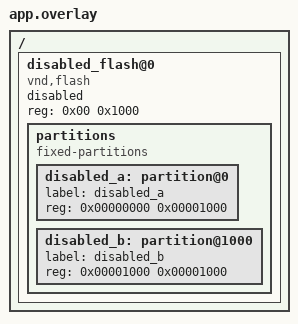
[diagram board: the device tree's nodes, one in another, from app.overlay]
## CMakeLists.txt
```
# SPDX-License-Identifier: Apache-2.0

cmake_minimum_required(VERSION 3.20.0)
find_package(Zephyr REQUIRED HINTS $ENV{ZEPHYR_BASE})
project(flash_map)

FILE(GLOB app_sources src/*.c)
target_sources(app PRIVATE ${app_sources})
```

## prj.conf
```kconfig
CONFIG_ZTEST=y
CONFIG_ZTEST_STACK_SIZE=2048
CONFIG_FLASH=y
CONFIG_FLASH_PAGE_LAYOUT=y
CONFIG_FLASH_MAP=y
CONFIG_FLASH_AREA_CHECK_INTEGRITY=y
```

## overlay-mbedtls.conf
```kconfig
CONFIG_FLASH_AREA_CHECK_INTEGRITY_MBEDTLS=y
```

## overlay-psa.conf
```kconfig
CONFIG_FLASH_AREA_CHECK_INTEGRITY_PSA=y
CONFIG_MBEDTLS=y
CONFIG_MBEDTLS_PSA_CRYPTO_C=y
```

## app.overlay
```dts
/*
 * Copyright (c) 2022, Commonwealth Scientific and Industrial Research
 * Organisation (CSIRO) ABN 41 687 119 230.
 *
 * SPDX-License-Identifier: Apache-2.0
 *
 * Test compilation with disabled flash nodes.
 */

/{
	disabled_flash@0 {
		compatible = "vnd,flash";
		reg = <0x00 0x1000>;
		status = "disabled";

		partitions {
			compatible = "fixed-partitions";
			#address-cells = <1>;
			#size-cells = <1>;

			disabled_a: partition@0 {
				label = "disabled_a";
				reg = <0x00000000 0x00001000>;
			};
			disabled_b: partition@1000 {
				label = "disabled_b";
				reg = <0x00001000 0x00001000>;
			};
		};
	};
};
```

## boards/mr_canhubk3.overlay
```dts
/*
 * Copyright 2023 NXP
 *
 * SPDX-License-Identifier: Apache-2.0
 */

#include "../app.overlay"

/*
 * Currently there's no support for mcuboot, so create a partition for this test.
 */
&mx25l6433f {
	partitions {
		slot1_partition: partition@100000 {
			reg = <0x100000 0x100000>;
		};
	};
};
```

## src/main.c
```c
/*
 * Copyright (c) 2017 Nordic Semiconductor ASA
 * Copyright (c) 2015 Runtime Inc
 * Copyright (c) 2020 Gerson Fernando Budke <nandojve@gmail.com>
 * Copyright 2024 NXP
 *
 * SPDX-License-Identifier: Apache-2.0
 */

#include <zephyr/ztest.h>
#include <zephyr/drivers/flash.h>
#include <zephyr/storage/flash_map.h>

#define SLOT1_PARTITION		slot1_partition
#define SLOT1_PARTITION_ID	FIXED_PARTITION_ID(SLOT1_PARTITION)
#define SLOT1_PARTITION_DEV	FIXED_PARTITION_DEVICE(SLOT1_PARTITION)
#define SLOT1_PARTITION_NODE	DT_NODELABEL(SLOT1_PARTITION)

extern int flash_map_entries;
struct flash_sector fs_sectors[1024];

ZTEST(flash_map, test_flash_area_disabled_device)
{
	const struct flash_area *fa;
	int rc;

	/* Test that attempting to open a disabled flash area fails */
	rc = flash_area_open(FIXED_PARTITION_ID(disabled_a), &fa);
	zassert_equal(rc, -ENODEV, "Open did not fail");
	rc = flash_area_open(FIXED_PARTITION_ID(disabled_b), &fa);
	zassert_equal(rc, -ENODEV, "Open did not fail");
}

/**
 * @brief Test flash_area_get_sectors()
 */
ZTEST(flash_map, test_flash_area_get_sectors)
{
	const struct flash_area *fa;
	uint32_t sec_cnt;
	int i;
	int rc;
	off_t off;
	uint8_t wd[512];
	uint8_t rd[512];
	const struct device *flash_dev;
	const struct device *flash_dev_a = SLOT1_PARTITION_DEV;

	rc = flash_area_open(SLOT1_PARTITION_ID, &fa);
	zassert_true(rc == 0, "flash_area_open() fail");

	/* First erase the area so it's ready for use. */
	flash_dev = flash_area_get_device(fa);

	/* Device obtained by label should match the one from fa object */
	zassert_equal(flash_dev, flash_dev_a, "Device for slot1_partition do not match");

	rc = flash_erase(flash_dev, fa->fa_off, fa->fa_size);
	zassert_true(rc == 0, "flash area erase fail");

	(void)memset(wd, 0xa5, sizeof(wd));

	sec_cnt = ARRAY_SIZE(fs_sectors);
	rc = flash_area_get_sectors(SLOT1_PARTITION_ID, &sec_cnt, fs_sectors);
	zassert_true(rc == 0, "flash_area_get_sectors failed");

	/* write stuff to beginning of every sector */
	off = 0;
	for (i = 0; i < sec_cnt; i++) {
		rc = flash_area_write(fa, off, wd, sizeof(wd));
		zassert_true(rc == 0, "flash_area_write() fail");

		/* read it back via hal_flash_Read() */
		rc = flash_read(flash_dev, fa->fa_off + off, rd, sizeof(rd));
		zassert_true(rc == 0, "hal_flash_read() fail");

		rc = memcmp(wd, rd, sizeof(wd));
		zassert_true(rc == 0, "read data != write data");

		/* write stuff to end of area */
		rc = flash_write(flash_dev, fa->fa_off + off +
					    fs_sectors[i].fs_size - sizeof(wd),
				 wd, sizeof(wd));
		zassert_true(rc == 0, "hal_flash_write() fail");

		/* and read it back */
		(void)memset(rd, 0, sizeof(rd));
		rc = flash_area_read(fa, off + fs_sectors[i].fs_size -
					 sizeof(rd),
				     rd, sizeof(rd));
		zassert_true(rc == 0, "hal_flash_read() fail");

		rc = memcmp(wd, rd, sizeof(rd));
		zassert_true(rc == 0, "read data != write data");

		off += fs_sectors[i].fs_size;
	}

	/* erase it */
	rc = flash_area_erase(fa, 0, fa->fa_size);
	zassert_true(rc == 0, "read data != write data");

	/* should read back ff all throughout*/
	(void)memset(wd, 0xff, sizeof(wd));
	for (off = 0; off < fa->fa_size; off += sizeof(rd)) {
		rc = flash_area_read(fa, off, rd, sizeof(rd));
		zassert_true(rc == 0, "hal_flash_read() fail");

		rc = memcmp(wd, rd, sizeof(rd));
		zassert_true(rc == 0, "area not erased");
	}

	flash_area_close(fa);
}

ZTEST(flash_map, test_flash_area_check_int_sha256)
{
	/* for i in {1..16}; do echo $'0123456789abcdef\nfedcba98765432' >> tst.sha; done
	 * hexdump tst.sha
	 */
	uint8_t tst_vec[] = { 0x30, 0x31, 0x32, 0x33, 0x34, 0x35, 0x36, 0x37,
			      0x38, 0x39, 0x61, 0x62, 0x63, 0x64, 0x65, 0x66,
			      0x0a, 0x66, 0x65, 0x64, 0x63, 0x62, 0x61, 0x39,
			      0x38, 0x37, 0x36, 0x35, 0x34, 0x33, 0x32, 0x0a,
			      0x30, 0x31, 0x32, 0x33, 0x34, 0x35, 0x36, 0x37,
			      0x38, 0x39, 0x61, 0x62, 0x63, 0x64, 0x65, 0x66,
			      0x0a, 0x66, 0x65, 0x64, 0x63, 0x62, 0x61, 0x39,
			      0x38, 0x37, 0x36, 0x35, 0x34, 0x33, 0x32, 0x0a,
			      0x30, 0x31, 0x32, 0x33, 0x34, 0x35, 0x36, 0x37,
			      0x38, 0x39, 0x61, 0x62, 0x63, 0x64, 0x65, 0x66,
			      0x0a, 0x66, 0x65, 0x64, 0x63, 0x62, 0x61, 0x39,
			      0x38, 0x37, 0x36, 0x35, 0x34, 0x33, 0x32, 0x0a,
			      0x30, 0x31, 0x32, 0x33, 0x34, 0x35, 0x36, 0x37,
			      0x38, 0x39, 0x61, 0x62, 0x63, 0x64, 0x65, 0x66,
			      0x0a, 0x66, 0x65, 0x64, 0x63, 0x62, 0x61, 0x39,
			      0x38, 0x37, 0x36, 0x35, 0x34, 0x33, 0x32, 0x0a,
			      0x30, 0x31, 0x32, 0x33, 0x34, 0x35, 0x36, 0x37,
			      0x38, 0x39, 0x61, 0x62, 0x63, 0x64, 0x65, 0x66,
			      0x0a, 0x66, 0x65, 0x64, 0x63, 0x62, 0x61, 0x39,
			      0x38, 0x37, 0x36, 0x35, 0x34, 0x33, 0x32, 0x0a,
			      0x30, 0x31, 0x32, 0x33, 0x34, 0x35, 0x36, 0x37,
			      0x38, 0x39, 0x61, 0x62, 0x63, 0x64, 0x65, 0x66,
			      0x0a, 0x66, 0x65, 0x64, 0x63, 0x62, 0x61, 0x39,
			      0x38, 0x37, 0x36, 0x35, 0x34, 0x33, 0x32, 0x0a,
			      0x30, 0x31, 0x32, 0x33, 0x34, 0x35, 0x36, 0x37,
			      0x38, 0x39, 0x61, 0x62, 0x63, 0x64, 0x65, 0x66,
			      0x0a, 0x66, 0x65, 0x64, 0x63, 0x62, 0x61, 0x39,
			      0x38, 0x37, 0x36, 0x35, 0x34, 0x33, 0x32, 0x0a,
			      0x30, 0x31, 0x32, 0x33, 0x34, 0x35, 0x36, 0x37,
			      0x38, 0x39, 0x61, 0x62, 0x63, 0x64, 0x65, 0x66,
			      0x0a, 0x66, 0x65, 0x64, 0x63, 0x62, 0x61, 0x39,
			      0x38, 0x37, 0x36, 0x35, 0x34, 0x33, 0x32, 0x0a,
			      0x30, 0x31, 0x32, 0x33, 0x34, 0x35, 0x36, 0x37,
			      0x38, 0x39, 0x61, 0x62, 0x63, 0x64, 0x65, 0x66,
			      0x0a, 0x66, 0x65, 0x64, 0x63, 0x62, 0x61, 0x39,
			      0x38, 0x37, 0x36, 0x35, 0x34, 0x33, 0x32, 0x0a,
			      0x30, 0x31, 0x32, 0x33, 0x34, 0x35, 0x36, 0x37,
			      0x38, 0x39, 0x61, 0x62, 0x63, 0x64, 0x65, 0x66,
			      0x0a, 0x66, 0x65, 0x64, 0x63, 0x62, 0x61, 0x39,
			      0x38, 0x37, 0x36, 0x35, 0x34, 0x33, 0x32, 0x0a,
			      0x30, 0x31, 0x32, 0x33, 0x34, 0x35, 0x36, 0x37,
			      0x38, 0x39, 0x61, 0x62, 0x63, 0x64, 0x65, 0x66,
			      0x0a, 0x66, 0x65, 0x64, 0x63, 0x62, 0x61, 0x39,
			      0x38, 0x37, 0x36, 0x35, 0x34, 0x33, 0x32, 0x0a,
			      0x30, 0x31, 0x32, 0x33, 0x34, 0x35, 0x36, 0x37,
			      0x38, 0x39, 0x61, 0x62, 0x63, 0x64, 0x65, 0x66,
			      0x0a, 0x66, 0x65, 0x64, 0x63, 0x62, 0x61, 0x39,
			      0x38, 0x37, 0x36, 0x35, 0x34, 0x33, 0x32, 0x0a,
			      0x30, 0x31, 0x32, 0x33, 0x34, 0x35, 0x36, 0x37,
			      0x38, 0x39, 0x61, 0x62, 0x63, 0x64, 0x65, 0x66,
			      0x0a, 0x66, 0x65, 0x64, 0x63, 0x62, 0x61, 0x39,
			      0x38, 0x37, 0x36, 0x35, 0x34, 0x33, 0x32, 0x0a,
			      0x30, 0x31, 0x32, 0x33, 0x34, 0x35, 0x36, 0x37,
			      0x38, 0x39, 0x61, 0x62, 0x63, 0x64, 0x65, 0x66,
			      0x0a, 0x66, 0x65, 0x64, 0x63, 0x62, 0x61, 0x39,
			      0x38, 0x37, 0x36, 0x35, 0x34, 0x33, 0x32, 0x0a,
			      0x30, 0x31, 0x32, 0x33, 0x34, 0x35, 0x36, 0x37,
			      0x38, 0x39, 0x61, 0x62, 0x63, 0x64, 0x65, 0x66,
			      0x0a, 0x66, 0x65, 0x64, 0x63, 0x62, 0x61, 0x39,
			      0x38, 0x37, 0x36, 0x35, 0x34, 0x33, 0x32, 0x0a,
			      0x30, 0x31, 0x32, 0x33, 0x34, 0x35, 0x36, 0x37,
			      0x38, 0x39, 0x61, 0x62, 0x63, 0x64, 0x65, 0x66,
			      0x0a, 0x66, 0x65, 0x64, 0x63, 0x62, 0x61, 0x39,
			      0x38, 0x37, 0x36, 0x35, 0x34, 0x33, 0x32, 0x0a };
	/* sha256sum tst.sha */
	uint8_t tst_sha[] = { 0xae, 0xed, 0x7d, 0x59, 0x53, 0xbd, 0xb7, 0x28,
			      0x3e, 0x59, 0xc2, 0x65, 0x59, 0x62, 0xe3, 0x7e,
			      0xfa, 0x97, 0xbd, 0x76, 0xf6, 0xac, 0xc3, 0x92,
			      0x59, 0x48, 0x4e, 0xc0, 0xaf, 0xa8, 0x49, 0x65 };

	const struct flash_area *fa;
	struct flash_area_check fac = { NULL, 0, -1, NULL, 0 };
	uint8_t buffer[16];
	int rc;

	rc = flash_area_open(SLOT1_PARTITION_ID, &fa);
	zassert_true(rc == 0, "flash_area_open() fail, error %d\n", rc);
	rc = flash_area_erase(fa, 0, fa->fa_size);
	zassert_true(rc == 0, "Flash erase failure (%d), error %d\n", rc);
	rc = flash_area_write(fa, 0, tst_vec, sizeof(tst_vec));
	zassert_true(rc == 0, "Flash img write, error %d\n", rc);

	rc = flash_area_check_int_sha256(NULL, NULL);
	zassert_true(rc == -EINVAL, "Flash area check int 256 params 1, 2\n");
	rc = flash_area_check_int_sha256(NULL, &fac);
	zassert_true(rc == -EINVAL, "Flash area check int 256 params 2\n");
	rc = flash_area_check_int_sha256(fa, NULL);
	zassert_true(rc == -EINVAL, "Flash area check int 256 params 1\n");

	rc = flash_area_check_int_sha256(fa, &fac);
	zassert_true(rc == -EINVAL, "Flash area check int 256 fac match\n");
	fac.match = tst_sha;
	rc = flash_area_check_int_sha256(fa, &fac);
	zassert_true(rc == -EINVAL, "Flash area check int 256 fac clen\n");
	fac.clen = sizeof(tst_vec);
	rc = flash_area_check_int_sha256(fa, &fac);
	zassert_true(rc == -EINVAL, "Flash area check int 256 fac off\n");
	fac.off = 0;
	rc = flash_area_check_int_sha256(fa, &fac);
	zassert_true(rc == -EINVAL, "Flash area check int 256 fac rbuf\n");
	fac.rbuf = buffer;
	rc = flash_area_check_int_sha256(fa, &fac);
	zassert_true(rc == -EINVAL, "Flash area check int 256 fac rblen\n");
	fac.rblen = sizeof(buffer);

	rc = flash_area_check_int_sha256(fa, &fac);
	zassert_true(rc == 0, "Flash area check int 256 OK, error %d\n", rc);
	tst_sha[0] = 0x00;
	rc = flash_area_check_int_sha256(fa, &fac);
	zassert_false(rc == 0, "Flash area check int 256 wrong sha\n");

	flash_area_close(fa);
}

ZTEST(flash_map, test_flash_area_erased_val)
{
	const struct flash_parameters *param;
	const struct flash_area *fa;
	uint8_t val;
	int rc;

	rc = flash_area_open(SLOT1_PARTITION_ID, &fa);
	zassert_true(rc == 0, "flash_area_open() fail");

	val = flash_area_erased_val(fa);

	param = flash_get_parameters(fa->fa_dev);

	zassert_equal(param->erase_value, val,
		      "value different than the flash erase value");

	flash_area_close(fa);
}

ZTEST(flash_map, test_fixed_partition_node_macros)
{
	/* Test against changes in API */
	zassert_equal(FIXED_PARTITION_NODE_OFFSET(SLOT1_PARTITION_NODE),
		DT_REG_ADDR(SLOT1_PARTITION_NODE));
	zassert_equal(FIXED_PARTITION_NODE_SIZE(SLOT1_PARTITION_NODE),
		DT_REG_SIZE(SLOT1_PARTITION_NODE));
	zassert_equal(FIXED_PARTITION_NODE_DEVICE(SLOT1_PARTITION_NODE),
		DEVICE_DT_GET(DT_MTD_FROM_FIXED_PARTITION(SLOT1_PARTITION_NODE)));
}

ZTEST(flash_map, test_flash_area_erase_and_flatten)
{
	int i;
	bool erased = true;
	int rc;
	const struct flash_area *fa;
	const struct device *flash_dev;

	rc = flash_area_open(SLOT1_PARTITION_ID, &fa);
	zassert_true(rc == 0, "flash_area_open() fail");

	/* First erase the area so it's ready for use. */
	flash_dev = flash_area_get_device(fa);

	rc = flash_erase(flash_dev, fa->fa_off, fa->fa_size);
	zassert_true(rc == 0, "flash area erase fail");

	rc = flash_fill(flash_dev, 0xaa, fa->fa_off, fa->fa_size);
	zassert_true(rc == 0, "flash device fill fail");

	rc = flash_area_erase(fa, 0, fa->fa_size);
	zassert_true(rc == 0, "flash area erase fail");

	TC_PRINT("Flash area info:\n");
	TC_PRINT("\tpointer:\t %p\n", &fa);
	TC_PRINT("\toffset:\t %ld\n", (long)fa->fa_off);
	TC_PRINT("\tsize:\t %ld\n", (long)fa->fa_size);

	/* we work under assumption that flash_fill is working and tested */
	i = 0;
	while (erased && i < fa->fa_size) {
		uint8_t buf[32];
		int chunk = MIN(sizeof(buf), fa->fa_size - i);

		rc = flash_read(flash_dev, fa->fa_off + i, buf, chunk);
		zassert_equal(rc, 0, "Unexpected read fail with error %d", rc);
		for (int ii = 0; ii < chunk; ++ii, ++i) {
			if ((uint8_t)buf[ii] != (uint8_t)flash_area_erased_val(fa)) {
				erased = false;
				break;
			}
		}
	}
	zassert_true(erased, "Erase failed at dev abosolute offset index %d",
		     i + fa->fa_off);

	rc = flash_fill(flash_dev, 0xaa, fa->fa_off, fa->fa_size);
	zassert_true(rc == 0, "flash device fill fail");

	rc = flash_area_flatten(fa, 0, fa->fa_size);

	erased = true;
	i = 0;
	while (erased && i < fa->fa_size) {
		uint8_t buf[32];
		int chunk = MIN(sizeof(buf), fa->fa_size - i);

		rc = flash_read(flash_dev, fa->fa_off + i, buf, chunk);
		zassert_equal(rc, 0, "Unexpected read fail with error %d", rc);
		for (int ii = 0; ii < chunk; ++ii, ++i) {
			if ((uint8_t)buf[ii] != (uint8_t)flash_area_erased_val(fa)) {
				erased = false;
				break;
			}
		}
	}
	zassert_true(erased, "Flatten/Erase failed at dev absolute offset %d",
		     i + fa->fa_off);
}

ZTEST_SUITE(flash_map, NULL, NULL, NULL, NULL, NULL);
```
